VERSION "SPECGO_TEMPLATE_1_0"

NS_ :

BS_:

BU_: ECU_TX ECU_RX

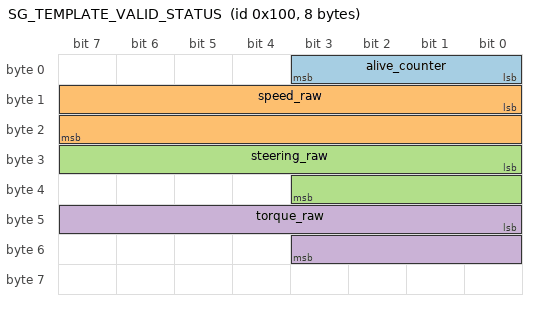
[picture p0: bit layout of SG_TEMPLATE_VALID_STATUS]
BO_ 256 SG_TEMPLATE_VALID_STATUS: 8 ECU_TX
 SG_ alive_counter : 0|4@1+ (1,0) [0|15] "" ECU_RX
 SG_ speed_raw : 8|16@1+ (1,0) [0|65535] "raw_kph" ECU_RX
 SG_ steering_raw : 24|12@1- (1,0) [-2048|2047] "raw_deg" ECU_RX
 SG_ torque_raw : 40|12@1- (1,0) [-2048|2047] "raw_nm" ECU_RX
